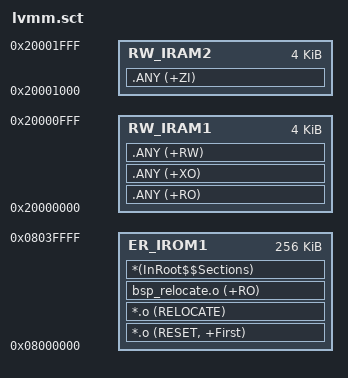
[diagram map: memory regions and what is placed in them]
; *************************************************************
; *** Scatter-Loading Description File generated by uVision ***
; *************************************************************

LR_IROM1 0x08000000 0x40000  {    ; load region size_region
  ER_IROM1 0x08000000 0x40000{				 ; load address != execution address
   *.o (RESET, +First)
   *.o (RELOCATE)
   bsp_relocate.o (+RO)
   *(InRoot$$Sections)

;   .ANY (+RO)
;   .ANY (+XO)
  }
  
  RW_IRAM1 0x20000000 0x1000{
   .ANY (+RO)
   .ANY (+XO)
   .ANY (+RW)
  }
  
  RW_IRAM2 0x20001000 0x1000{  ; RW data
   .ANY (+ZI)
  }
  

}

